AUTOSAR XML (schema 4-3-0)
package /BMS_Component
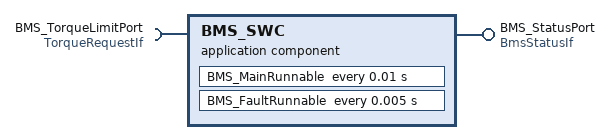
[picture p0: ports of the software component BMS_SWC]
  application sw component type BMS_SWC
    provide port BMS_StatusPort: provided-interface=BmsStatusIf
    require port BMS_TorqueLimitPort: required-interface=TorqueRequestIf
    behavior BMS_SWC_InternalBehavior
      timing event TET_BMS_MainRunnable: start-on-event=BMS_MainRunnable, period=0.01
      timing event TET_BMS_FaultRunnable: start-on-event=BMS_FaultRunnable, period=0.005
      runnable BMS_MainRunnable: symbol=Bms_MainFunction
      runnable BMS_FaultRunnable: symbol=Bms_FaultFunction
